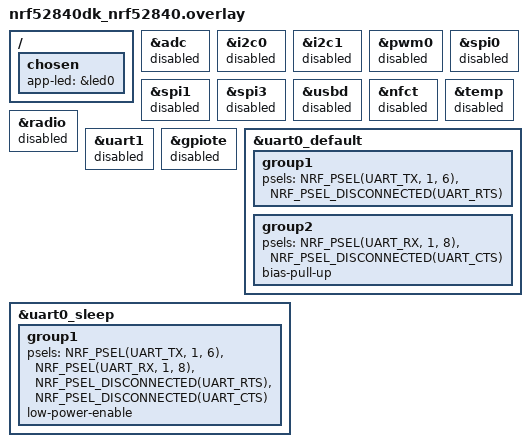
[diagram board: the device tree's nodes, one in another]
/ {
    chosen {
        app-led = &led0;
    };
};

// Disable unused peripherals to reduce power consumption.
&adc {status = "disabled"; };
&i2c0 {status = "disabled"; };
&i2c1 {status = "disabled"; };
&pwm0 {status = "disabled"; };
&spi0 {status = "disabled"; };
&spi1 {status = "disabled"; };
&spi3 {status = "disabled"; };
&usbd {status = "disabled"; };
&nfct {status = "disabled"; };
&temp {status = "disabled"; };
&radio {status = "disabled"; };
&uart1 {status = "disabled"; };
&gpiote {status = "disabled"; };

// Overwrite the UART pin control to use different pins.
&uart0_default {
  group1 {
    psels = <NRF_PSEL(UART_TX, 1, 6)>, <NRF_PSEL_DISCONNECTED(UART_RTS)>;
  };
  group2 {
    psels = <NRF_PSEL(UART_RX, 1, 8)>, <NRF_PSEL_DISCONNECTED(UART_CTS)>;
    bias-pull-up;
  };
};
&uart0_sleep {
  group1 {
    psels =
      <NRF_PSEL(UART_TX, 1, 6)>,  <NRF_PSEL(UART_RX, 1, 8)>,
      <NRF_PSEL_DISCONNECTED(UART_RTS)>, <NRF_PSEL_DISCONNECTED(UART_CTS)>;
    low-power-enable;
  };
};
